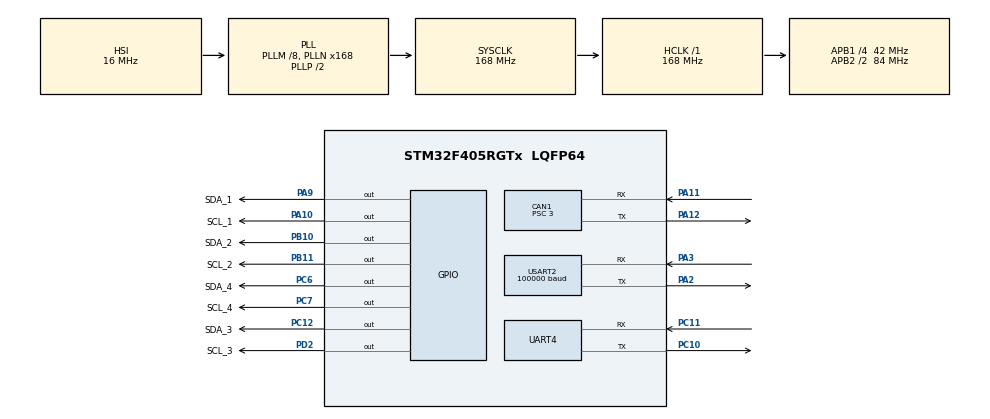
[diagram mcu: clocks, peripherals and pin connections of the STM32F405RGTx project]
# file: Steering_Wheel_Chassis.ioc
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CAN1.BS1=CAN_BS1_9TQ
CAN1.BS2=CAN_BS2_4TQ
CAN1.CalculateBaudRate=1000000
CAN1.CalculateTimeBit=1000
CAN1.CalculateTimeQuantum=71.42857142857143
CAN1.Prescaler=3
Dma.Request0=USART2_RX
Dma.Request1=UART4_TX
Dma.UART4_TX.1.Direction=DMA_MEMORY_TO_PERIPH
Dma.UART4_TX.1.FIFOMode=DMA_FIFOMODE_DISABLE
Dma.UART4_TX.1.Instance=DMA1_Stream4
Dma.UART4_TX.1.MemDataAlignment=DMA_MDATAALIGN_BYTE
Dma.UART4_TX.1.MemInc=DMA_MINC_ENABLE
Dma.UART4_TX.1.Mode=DMA_CIRCULAR
Dma.UART4_TX.1.PeriphDataAlignment=DMA_PDATAALIGN_BYTE
Dma.UART4_TX.1.PeriphInc=DMA_PINC_DISABLE
Dma.UART4_TX.1.Priority=DMA_PRIORITY_LOW
Dma.USART2_RX.0.Direction=DMA_PERIPH_TO_MEMORY
Dma.USART2_RX.0.FIFOMode=DMA_FIFOMODE_DISABLE
Dma.USART2_RX.0.Instance=DMA1_Stream5
Dma.USART2_RX.0.MemDataAlignment=DMA_MDATAALIGN_BYTE
Dma.USART2_RX.0.MemInc=DMA_MINC_ENABLE
Dma.USART2_RX.0.Mode=DMA_CIRCULAR
Dma.USART2_RX.0.PeriphDataAlignment=DMA_PDATAALIGN_BYTE
Dma.USART2_RX.0.PeriphInc=DMA_PINC_DISABLE
Dma.USART2_RX.0.Priority=DMA_PRIORITY_LOW
FREERTOS.BinarySemaphores01=DbusReady,Dynamic,NULL,Depleted
FREERTOS.Queues01=Signal_Queue,16,uint16_t,0,Dynamic,NULL,NULL
FREERTOS.Tasks01=defaultTask,24,128,StartDefaultTask,Default,NULL,Dynamic,NULL,NULL;Receive_Handle,8,256,Receive_and_Process_Signal,As weak,NULL,Dynamic,NULL,NULL;Movement_Handle,8,512,Motor_Movement,As weak,NULL,Dynamic,NULL,NULL;Vofa_Transmit,8,128,Vofa_Debugging_Transmition,As weak,NULL,Dynamic,NULL,NULL
Mcu.Family=STM32F4
Mcu.Name=STM32F405RGTx
Mcu.Package=LQFP64
NVIC.CAN1_RX0_IRQn=true\:5\:0\:false\:false\:true\:true\:true\:true\:true
NVIC.DMA1_Stream4_IRQn=true\:5\:0\:false\:false\:true\:true\:false\:true\:true
NVIC.DMA1_Stream5_IRQn=true\:5\:0\:false\:false\:true\:true\:false\:true\:true
NVIC.PriorityGroup=NVIC_PRIORITYGROUP_4
NVIC.TIM1_UP_TIM10_IRQn=true\:15\:0\:false\:false\:true\:false\:false\:true\:true
NVIC.TimeBase=TIM1_UP_TIM10_IRQn
NVIC.TimeBaseIP=TIM1
NVIC.UART4_IRQn=true\:5\:0\:false\:false\:true\:true\:false\:true\:true
NVIC.USART2_IRQn=true\:5\:0\:false\:false\:true\:true\:true\:true\:true
PA10.GPIO_Label=SCL_1
PA10.GPIO_ModeDefaultOutputPP=GPIO_MODE_OUTPUT_OD
PA10.GPIO_PuPd=GPIO_PULLUP
PA10.Signal=GPIO_Output
PA11.Mode=CAN_Activate
PA11.Signal=CAN1_RX
PA12.Mode=CAN_Activate
PA12.Signal=CAN1_TX
PA13.Mode=Serial_Wire
PA13.Signal=SYS_JTMS-SWDIO
PA14.Mode=Serial_Wire
PA14.Signal=SYS_JTCK-SWCLK
PA2.Mode=Asynchronous
PA2.Signal=USART2_TX
PA3.Mode=Asynchronous
PA3.Signal=USART2_RX
PA9.GPIO_Label=SDA_1
PA9.GPIO_ModeDefaultOutputPP=GPIO_MODE_OUTPUT_OD
PA9.GPIO_PuPd=GPIO_PULLUP
PA9.Signal=GPIO_Output
PB10.GPIO_Label=SDA_2
PB10.GPIO_ModeDefaultOutputPP=GPIO_MODE_OUTPUT_OD
PB10.GPIO_PuPd=GPIO_PULLUP
PB10.Signal=GPIO_Output
PB11.GPIO_Label=SCL_2
PB11.GPIO_ModeDefaultOutputPP=GPIO_MODE_OUTPUT_OD
PB11.GPIO_PuPd=GPIO_PULLUP
PB11.Signal=GPIO_Output
PC10.Mode=Asynchronous
PC10.Signal=UART4_TX
PC11.Mode=Asynchronous
PC11.Signal=UART4_RX
PC12.GPIO_Label=SDA_3
PC12.GPIO_ModeDefaultOutputPP=GPIO_MODE_OUTPUT_OD
PC12.GPIO_PuPd=GPIO_PULLUP
PC12.Signal=GPIO_Output
PC6.GPIO_Label=SDA_4
PC6.GPIO_ModeDefaultOutputPP=GPIO_MODE_OUTPUT_OD
PC6.GPIO_PuPd=GPIO_PULLUP
PC6.Signal=GPIO_Output
PC7.GPIO_Label=SCL_4
PC7.GPIO_ModeDefaultOutputPP=GPIO_MODE_OUTPUT_OD
PC7.GPIO_PuPd=GPIO_PULLUP
PC7.Signal=GPIO_Output
PD2.GPIO_Label=SCL_3
PD2.GPIO_ModeDefaultOutputPP=GPIO_MODE_OUTPUT_OD
PD2.GPIO_PuPd=GPIO_PULLUP
PD2.Signal=GPIO_Output
PH0-OSC_IN.Mode=HSE-External-Oscillator
PH0-OSC_IN.Signal=RCC_OSC_IN
PH1-OSC_OUT.Mode=HSE-External-Oscillator
PH1-OSC_OUT.Signal=RCC_OSC_OUT
ProjectManager.HeapSize=0x200
ProjectManager.StackSize=0x400
ProjectManager.TargetToolchain=MDK-ARM V5.32
RCC.48MHZClocksFreq_Value=84000000
RCC.AHBFreq_Value=168000000
RCC.APB1CLKDivider=RCC_HCLK_DIV4
RCC.APB1Freq_Value=42000000
RCC.APB1TimFreq_Value=84000000
RCC.APB2CLKDivider=RCC_HCLK_DIV2
RCC.APB2Freq_Value=84000000
RCC.APB2TimFreq_Value=168000000
RCC.CortexFreq_Value=168000000
RCC.HCLKFreq_Value=168000000
RCC.HSE_VALUE=25000000
RCC.HSI_VALUE=16000000
RCC.LSE_VALUE=32768
RCC.PLLM=8
RCC.PLLN=168
RCC.SYSCLKFreq_VALUE=168000000
RCC.SYSCLKSource=RCC_SYSCLKSOURCE_PLLCLK
RCC.VCOOutputFreq_Value=336000000
UART4.VirtualMode=Asynchronous
USART2.BaudRate=100000
USART2.Parity=PARITY_EVEN
USART2.VirtualMode=VM_ASYNC
VP_FREERTOS_VS_CMSIS_V2.Mode=CMSIS_V2
VP_SYS_VS_tim1.Mode=TIM1
board=custom

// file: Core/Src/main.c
/* USER CODE BEGIN Header */
/**
  ******************************************************************************
  * @file           : main.c
  * @brief          : Main program body
  ******************************************************************************
  * @attention
  *
  * Copyright (c) 2026 STMicroelectronics.
  * All rights reserved.
  *
  * This software is licensed under terms that can be found in the LICENSE file
  * in the root directory of this software component.
  * If no LICENSE file comes with this software, it is provided AS-IS.
  *
  ******************************************************************************
  */
/* USER CODE END Header */
#include "main.h"
#include "cmsis_os.h"
#include "can.h"
#include "dma.h"
#include "usart.h"
#include "gpio.h"

void SystemClock_Config(void);
void MX_FREERTOS_Init(void);

int main(void)
{

  /* MCU Configuration--------------------------------------------------------*/

  /* Reset of all peripherals, Initializes the Flash interface and the Systick. */
  HAL_Init();

  /* Configure the system clock */
  SystemClock_Config();

  /* Initialize all configured peripherals */
  MX_GPIO_Init();
  MX_DMA_Init();
  MX_CAN1_Init();
  MX_USART2_UART_Init();
  MX_UART4_Init();

  /* Init scheduler */
  osKernelInitialize();  /* Call init function for freertos objects (in cmsis_os2.c) */
  MX_FREERTOS_Init();

  /* Start scheduler */
  osKernelStart();

  /* We should never get here as control is now taken by the scheduler */

  /* Infinite loop */
  while (1)
  {

  }
}

void SystemClock_Config(void)
{
  RCC_OscInitTypeDef RCC_OscInitStruct = {0};
  RCC_ClkInitTypeDef RCC_ClkInitStruct = {0};

  /** Configure the main internal regulator output voltage
  */
  __HAL_RCC_PWR_CLK_ENABLE();
  __HAL_PWR_VOLTAGESCALING_CONFIG(PWR_REGULATOR_VOLTAGE_SCALE1);

  /** Initializes the RCC Oscillators according to the specified parameters
  * in the RCC_OscInitTypeDef structure.
  */
  RCC_OscInitStruct.OscillatorType = RCC_OSCILLATORTYPE_HSI;
  RCC_OscInitStruct.HSIState = RCC_HSI_ON;
  RCC_OscInitStruct.HSICalibrationValue = RCC_HSICALIBRATION_DEFAULT;
  RCC_OscInitStruct.PLL.PLLState = RCC_PLL_ON;
  RCC_OscInitStruct.PLL.PLLSource = RCC_PLLSOURCE_HSI;
  RCC_OscInitStruct.PLL.PLLM = 8;
  RCC_OscInitStruct.PLL.PLLN = 168;
  RCC_OscInitStruct.PLL.PLLP = RCC_PLLP_DIV2;
  RCC_OscInitStruct.PLL.PLLQ = 4;
  if (HAL_RCC_OscConfig(&RCC_OscInitStruct) != HAL_OK)
  {
    Error_Handler();
  }

  /** Initializes the CPU, AHB and APB buses clocks
  */
  RCC_ClkInitStruct.ClockType = RCC_CLOCKTYPE_HCLK|RCC_CLOCKTYPE_SYSCLK
                              |RCC_CLOCKTYPE_PCLK1|RCC_CLOCKTYPE_PCLK2;
  RCC_ClkInitStruct.SYSCLKSource = RCC_SYSCLKSOURCE_PLLCLK;
  RCC_ClkInitStruct.AHBCLKDivider = RCC_SYSCLK_DIV1;
  RCC_ClkInitStruct.APB1CLKDivider = RCC_HCLK_DIV4;
  RCC_ClkInitStruct.APB2CLKDivider = RCC_HCLK_DIV2;

  if (HAL_RCC_ClockConfig(&RCC_ClkInitStruct, FLASH_LATENCY_5) != HAL_OK)
  {
    Error_Handler();
  }
}

void HAL_TIM_PeriodElapsedCallback(TIM_HandleTypeDef *htim)
{
  if (htim->Instance == TIM1)
  {
    HAL_IncTick();
  }
}

void Error_Handler(void)
{
  __disable_irq();
  while (1)
  {
  }
}

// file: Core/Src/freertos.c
/* USER CODE BEGIN Header */
/**
  ******************************************************************************
  * File Name          : freertos.c
  * Description        : Code for freertos applications
  ******************************************************************************
  * @attention
  *
  * Copyright (c) 2026 STMicroelectronics.
  * All rights reserved.
  *
  * This software is licensed under terms that can be found in the LICENSE file
  * in the root directory of this software component.
  * If no LICENSE file comes with this software, it is provided AS-IS.
  *
  ******************************************************************************
  */
/* USER CODE END Header */

#include "FreeRTOS.h"
#include "task.h"
#include "main.h"
#include "cmsis_os.h"

/* USER CODE BEGIN Includes */
#include "movement_task.h"
#include "remote_control_task.h"
#include "vofa_transmit_task.h"
#include "../../Hardwares/config.h"
/* USER CODE END Includes */

/* Definitions for defaultTask */
osThreadId_t defaultTaskHandle;
const osThreadAttr_t defaultTask_attributes = {
  .name = "defaultTask",
  .stack_size = 128 * 4,
  .priority = (osPriority_t) osPriorityNormal,
};
/* Definitions for Receive_Handle */
osThreadId_t Receive_HandleHandle;
const osThreadAttr_t Receive_Handle_attributes = {
  .name = "Receive_Handle",
  .stack_size = 256 * 4,
  .priority = (osPriority_t) osPriorityLow,
};
/* Definitions for Movement_Handle */
osThreadId_t Movement_HandleHandle;
const osThreadAttr_t Movement_Handle_attributes = {
  .name = "Movement_Handle",
  .stack_size = 512 * 4,
  .priority = (osPriority_t) osPriorityLow,
};
/* Definitions for Vofa_Transmit */
osThreadId_t Vofa_TransmitHandle;
const osThreadAttr_t Vofa_Transmit_attributes = {
  .name = "Vofa_Transmit",
  .stack_size = 128 * 4,
  .priority = (osPriority_t) osPriorityLow,
};
/* Definitions for Signal_Queue */
osMessageQueueId_t Signal_QueueHandle;
const osMessageQueueAttr_t Signal_Queue_attributes = {
  .name = "Signal_Queue"
};
/* Definitions for DbusReady */
osSemaphoreId_t DbusReadyHandle;
const osSemaphoreAttr_t DbusReady_attributes = {
  .name = "DbusReady"
};

void StartDefaultTask(void *argument);
void Receive_and_Process_Signal(void *argument);
void Motor_Movement(void *argument);
void Vofa_Debugging_Transmition(void *argument);

void MX_FREERTOS_Init(void); /* (MISRA C 2004 rule 8.1) */

void MX_FREERTOS_Init(void) {
  /* USER CODE BEGIN Init */
  /* 初始化运动控制子系统（M3508 + MT6701 + 舵轮底盘） */
  Movement_Init();
  /* USER CODE END Init */

  /* Create the semaphores(s) */
  /* creation of DbusReady */
  DbusReadyHandle = osSemaphoreNew(1, 0, &DbusReady_attributes);

  /* Create the queue(s) */
  /* creation of Signal_Queue */
  Signal_QueueHandle = osMessageQueueNew(16, sizeof(ChassisVelocityCmd), &Signal_Queue_attributes);

  /* USER CODE BEGIN RTOS_QUEUES */
  /* add queues, ... */

  /*
   * 遥控子系统初始化必须放在信号量和队列创建之后，
   * 否则 UART IDLE 中断可能在 DbusReadyHandle 有效前触发，
   * ISR 中 xSemaphoreGiveFromISR(NULL) → HardFault
   */
  RemoteControlTask_Init();
  /* USER CODE END RTOS_QUEUES */

  /* Create the thread(s) */
  /* creation of defaultTask */
  defaultTaskHandle = osThreadNew(StartDefaultTask, NULL, &defaultTask_attributes);

  /* creation of Receive_Handle */
  Receive_HandleHandle = osThreadNew(Receive_and_Process_Signal, NULL, &Receive_Handle_attributes);

  /* creation of Movement_Handle */
  Movement_HandleHandle = osThreadNew(Motor_Movement, NULL, &Movement_Handle_attributes);

  /* creation of Vofa_Transmit */
  Vofa_TransmitHandle = osThreadNew(Vofa_Debugging_Transmition, NULL, &Vofa_Transmit_attributes);

}

void StartDefaultTask(void *argument)
{
  for(;;)
  {
    osDelay(1);
  }
}

__weak void Receive_and_Process_Signal(void *argument)
{
  /* USER CODE BEGIN Receive_and_Process_Signal */
  /* 任务实现在 Tasks/Remote_Control/remote_control_task.c */
  for(;;)
  {
    osDelay(1);
  }
  /* USER CODE END Receive_and_Process_Signal */
}

__weak void Motor_Movement(void *argument)
{
  /* USER CODE BEGIN Motor_Movement */
  /* 任务实现在 Tasks/Movement/movement_task.c */
  for(;;)
  {
    osDelay(1);
  }
  /* USER CODE END Motor_Movement */
}

__weak void Vofa_Debugging_Transmition(void *argument)
{
  for(;;)
  {
    osDelay(1);
  }
}

/* USER CODE BEGIN Application */
/* 中断回调已移至 Tasks 层：
 *   HAL_CAN_RxFifo0MsgPendingCallback  -> Tasks/Movement/movement_task.c
 *   HAL_UARTEx_RxEventCallback          -> Tasks/Remote_Control/remote_control_task.c
 */
/* USER CODE END Application */
